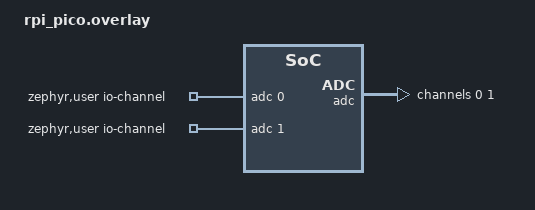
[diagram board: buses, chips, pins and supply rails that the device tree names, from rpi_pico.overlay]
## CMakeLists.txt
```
cmake_minimum_required(VERSION 3.20.0)
set(CMAKE_CXX_STANDARD 17)
#SET(CMAKE_CXX_FLAGS "${CMAKE_CXX_FLAGS} -std=c++14") 
set(BOARD rpi_pico)

#drivers
#include_directories(include)
#list(APPEND ZEPHYR_EXTRA_MODULES ${CMAKE_CURRENT_SOURCE_DIR}/drivers)

find_package(Zephyr REQUIRED HINTS $ENV{ZEPHYR_BASE})
project(payload)

#target_sources(app PRIVATE src/main.cpp)
include_directories(src)
file(GLOB_RECURSE SRCS src/**.cpp)
target_sources(app PRIVATE ${SRCS})
```

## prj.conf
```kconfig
CONFIG_CPLUSPLUS=y
CONFIG_NEWLIB_LIBC=y
CONFIG_LIB_CPLUSPLUS=y
CONFIG_NEWLIB_LIBC_FLOAT_PRINTF=y

CONFIG_GPIO=y
CONFIG_SENSOR=y
CONFIG_I2C=y
CONFIG_BME280=y
CONFIG_ADC=y

CONFIG_STDOUT_CONSOLE=y
CONFIG_PRINTK=y
CONFIG_PWM=y
CONFIG_LOG=y
CONFIG_LOG_PRINTK=y
CONFIG_LOG_MODE_IMMEDIATE=y
CONFIG_PWM_LOG_LEVEL_DBG=y
```

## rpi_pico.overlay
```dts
/ {
	zephyr,user {
		io-channels = <&adc 0>, <&adc 1>;
	};
};

&pinctrl{
	led: led {
        compatible = "gpio-ctrl";
        gpios = <&gpio0 25 0x0>;
    };
};

&adc {
	#address-cells = <1>;
	#size-cells = <0>;
	status = "okay";
	channel@0 {
		reg = <0>;
		zephyr,gain = "ADC_GAIN_1";
		zephyr,reference = "ADC_REF_INTERNAL";
		zephyr,acquisition-time = <ADC_ACQ_TIME_DEFAULT>;
		zephyr,resolution = <12>;
	};

	channel@1 {
		reg = <1>;
		zephyr,gain = "ADC_GAIN_1";
		zephyr,reference = "ADC_REF_INTERNAL";
		zephyr,acquisition-time = <ADC_ACQ_TIME_DEFAULT>;
		zephyr,resolution = <12>;
	};
};
```

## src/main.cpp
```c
/*
 * Copyright (c) 2023 Libre Solar Technologies GmbH
 *
 * SPDX-License-Identifier: Apache-2.0
 */

#include <stdio.h>
#include <inttypes.h>
#include <stddef.h>
#include <stdint.h>

#include <zephyr/devicetree.h>
#include <zephyr/device.h>
#include <zephyr/drivers/gpio.h>
#include <zephyr/drivers/sensor.h>
#include <zephyr/kernel.h>
#include <zephyr/sys/printk.h>
#include <zephyr/sys/util.h>

#include "drivers/adc/adc.hpp"

int main(void)
{
	printk("start\n");
	drivers::adc::Adc adc;
    while(1){
		// printk("main\n");
		k_msleep(1000);
		double voltage = adc.getVoltage();
		double speed = adc.getPitotSpeed();
		printk("Voltage: %f\n", voltage);
		printk("Pitot: %lf\n", speed);
    }
	return 0;
}
```
